# RL6842_IP_SVD register map
Vendor: Realtek
Registers are 32-bit, read-write, reset 0x0 unless marked. A register's access mark holds for its fields unless they carry their own. Offsets are from the block's base; [hi:lo] are bit positions; {n}, {i} and the like mark numbered series; <NAME> marks a mode.

## page6 (part 3 of 3)
Base 0x40000000
0x160C REG_A1_ADDR_MASK reset 0xFFFFFFFF — A1 Addr Mask Register
  [31:0] BIT_A1_ADDR_MASK — mask rx A1 addr [39:8] for test
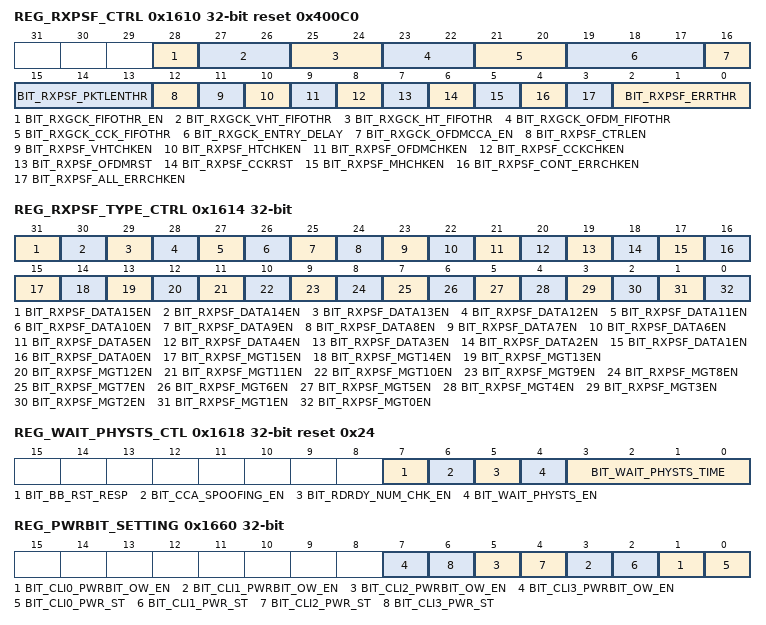
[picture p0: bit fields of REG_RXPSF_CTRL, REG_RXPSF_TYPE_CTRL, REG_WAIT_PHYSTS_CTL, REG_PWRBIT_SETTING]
0x1610 REG_RXPSF_CTRL reset 0x400C0
  [28] BIT_RXGCK_FIFOTHR_EN — 1: enable RXGCK fifo threshold 0: disable RXGCK fifo threshold (ignore fifo threshold) Should be 0 if MAC loopback mode
  [27:26] BIT_RXGCK_VHT_FIFOTHR — VHT rate RXGCK fifo threshold If RXVHT = 1 and RXGCK fifo write pointer >= this threshold, MAC_RX clock will stop gating. 0: 0 1: 1 (minimum RDRDY threshold for avoiding false alarm), can work at all situation. 2: 3 (number of RDRDY before receiving MAC header - 1), may cause error at some situation. 3: 4 (number of RDRDY before receiving MAC header), may cause error at some situation.
  [25:24] BIT_RXGCK_HT_FIFOTHR — HT rate RXGCK fifo threshold If RXHT = 1 and RXGCK fifo write pointer >= this threshold, MAC_RX clock will stop gating. 0: 0 1: 1 (minimum RDRDY threshold for avoiding false alarm), can work at all situation. 2: 2 (number of RDRDY before receiving MAC header - 1), may cause error at some situation. 3: 3 (number of RDRDY before receiving MAC header), may cause error at some situation.
  [23:22] BIT_RXGCK_OFDM_FIFOTHR — OFDM rate RXGCK fifo threshold If OFDM_VBON = 1 and RXGCK fifo write pointer >= this threshold, MAC_RX clock will stop gating. 0: 0 1: 1 (number of RDRDY before receiving MAC header = minimum RDRDY threshold for avoiding false alarm), can work at all situation. 2: 2, may cause error at some situation. 3: 3 (minimum RDRDY number within one packet), may cause error at some situation.
  [21:20] BIT_RXGCK_CCK_FIFOTHR — CCK rate RXGCK fifo threshold If CCKCCA = 1 and RXGCK fifo write pointer >= this threshold, MAC_RX clock will stop gating. 0: 0 1: 1 (minimum RDRDY threshold for avoiding false alarm), can work at all situation. 2: 8, may cause error at some situation. 3: 15 (number of RDRDY before receiving MAC header), may cause error at some situation.
  [19:17] BIT_RXGCK_ENTRY_DELAY — MAC_RX wait some time to gate clock after making the decision (about gating clock). Unit: T (MAC clock cycle) 0: 0 1: 2 2: 4 3: 8 4: 16 5: 32 6: 64 7: 128
  [16] BIT_RXGCK_OFDMCCA_EN — This bit is set to 1 to let OFDMCCA be one of the signals that can wakeup MAC from Rx_idle
  [15:13] BIT_RXPSF_PKTLENTHR — Packet length threshold 3'd0: 16 Bytes 3'd1: 32 Bytes 3'd2: 64 Bytes 3'd3: 128 Bytes 3'd4: 256 Bytes 3'd5: 512 Bytes 3'd6: 1024 Bytes 3'd7: 2048 Bytes Only the packet which packet length is longer than this threshold will trigger an invalid_pkt pulse.
  [12] BIT_RXPSF_CTRLEN — This bit is set to 1 to enable MAC to consider trigging invalid_pkt as rx packet Type=01.
  [11] BIT_RXPSF_VHTCHKEN — This bit is set to 1 to enable MAC to consider trigging invalid_pkt as rx packet rate = VHT
  [10] BIT_RXPSF_HTCHKEN — This bit is set to 1 to enable MAC to consider trigging invalid_pkt as rx packet rate = HT
  [9] BIT_RXPSF_OFDMCHKEN — This bit is set to 1 to enable MAC to consider trigging invalid_pkt as rx packet rate = OFDM
  [8] BIT_RXPSF_CCKCHKEN — This bit is set to 1 to enable MAC to consider trigging invalid_pkt as rx packet rate = CCK
  [7] BIT_RXPSF_OFDMRST — This bit is set to 1 to reset MAC Rx before sending OFDM (include OFDM, HT, VHT) packet triggered invalid_pkt pulse (0 for debug)
  [6] BIT_RXPSF_CCKRST — This bit is set to 1 to reset MAC Rx before sending CCK packet triggered invalid_pkt pulse(0 for debug)
  [5] BIT_RXPSF_MHCHKEN — This bit is set to 1 to enable MAC to inform BB enter power saving mode as rx unmatch my MACID unicast or unmatch my BSSID Broadcast/Mutlicast packets (including aggrigation and non-aggrigation)
  [4] BIT_RXPSF_CONT_ERRCHKEN — This bit is set to 1 to enable MAC to inform BB enter power saving mode as continuous rx FCS error packets number in a PPDU is large than the FCS error packet threshold defined by BBPSF_ERRTHR. This function is independent from rate, type and IDs.
  [3] BIT_RXPSF_ALL_ERRCHKEN — This bit is set to 1 to enable MAC to inform BB enter power saving mode as rx FCS error packets number in a PPDU is larger than the FCS error packet threshold defined by BBPSF_ERRTHR. This function is independent from rate, type and IDs.
  [2:0] BIT_RXPSF_ERRTHR — FCS error packet threshold 3'd0: 1 packet 3'd1: 4 packets 3'd2: 8 packets 3'd3: 12 packets 3'd4: 16 packets 3'd5: 20 packets 3'd6: 24 packets 3'd7: 28 packets
0x1614 REG_RXPSF_TYPE_CTRL
  [31] BIT_RXPSF_DATA15EN — This bit is set to 1 to enable MAC to consider trigging invalid_pkt as rx packet Type=10 and subtype=1111.
  [30] BIT_RXPSF_DATA14EN — This bit is set to 1 to enable MAC to consider trigging invalid_pkt as rx packet Type=10 and subtype=1110.
  [29] BIT_RXPSF_DATA13EN — This bit is set to 1 to enable MAC to consider trigging invalid_pkt as rx packet Type=10 and subtype=1101.
  [28] BIT_RXPSF_DATA12EN — This bit is set to 1 to enable MAC to consider trigging invalid_pkt as rx packet Type=10 and subtype=1100.
  [27] BIT_RXPSF_DATA11EN — This bit is set to 1 to enable MAC to consider trigging invalid_pkt as rx packet Type=10 and subtype=1011.
  [26] BIT_RXPSF_DATA10EN — This bit is set to 1 to enable MAC to consider trigging invalid_pkt as rx packet Type=10 and subtype=1010.
  [25] BIT_RXPSF_DATA9EN — This bit is set to 1 to enable MAC to consider trigging invalid_pkt as rx packet Type=10 and subtype=1001.
  [24] BIT_RXPSF_DATA8EN — This bit is set to 1 to enable MAC to consider trigging invalid_pkt as rx packet Type=10 and subtype=1000.
  [23] BIT_RXPSF_DATA7EN — This bit is set to 1 to enable MAC to consider trigging invalid_pkt as rx packet Type=10 and subtype=0111.
  [22] BIT_RXPSF_DATA6EN — This bit is set to 1 to enable MAC to consider trigging invalid_pkt as rx packet Type=10 and subtype=0110.
  [21] BIT_RXPSF_DATA5EN — This bit is set to 1 to enable MAC to consider trigging invalid_pkt as rx packet Type=10 and subtype=0101.
  [20] BIT_RXPSF_DATA4EN — This bit is set to 1 to enable MAC to consider trigging invalid_pkt as rx packet Type=10 and subtype=0100.
  [19] BIT_RXPSF_DATA3EN — This bit is set to 1 to enable MAC to consider trigging invalid_pkt as rx packet Type=10 and subtype=0011.
  [18] BIT_RXPSF_DATA2EN — This bit is set to 1 to enable MAC to consider trigging invalid_pkt as rx packet Type=10 and subtype=0010.
  [17] BIT_RXPSF_DATA1EN — This bit is set to 1 to enable MAC to consider trigging invalid_pkt as rx packet Type=10 and subtype=0001.
  [16] BIT_RXPSF_DATA0EN — This bit is set to 1 to enable MAC to consider trigging invalid_pkt as rx packet Type=10 and subtype=0000.
  [15] BIT_RXPSF_MGT15EN — This bit is set to 1 to enable MAC to consider trigging invalid_pkt as rx packet Type=00 and subtype=1111.
  [14] BIT_RXPSF_MGT14EN — This bit is set to 1 to enable MAC to consider trigging invalid_pkt as rx packet Type=00 and subtype=1110.
  [13] BIT_RXPSF_MGT13EN — This bit is set to 1 to enable MAC to consider trigging invalid_pkt as rx packet Type=00 and subtype=1101.
  [12] BIT_RXPSF_MGT12EN — This bit is set to 1 to enable MAC to consider trigging invalid_pkt as rx packet Type=00 and subtype=1100.
  [11] BIT_RXPSF_MGT11EN — This bit is set to 1 to enable MAC to consider trigging invalid_pkt as rx packet Type=00 and subtype=1011.
  [10] BIT_RXPSF_MGT10EN — This bit is set to 1 to enable MAC to consider trigging invalid_pkt as rx packet Type=00 and subtype=1010.
  [9] BIT_RXPSF_MGT9EN — This bit is set to 1 to enable MAC to consider trigging invalid_pkt as rx packet Type=00 and subtype=1001.
  [8] BIT_RXPSF_MGT8EN — This bit is set to 1 to enable MAC to consider trigging invalid_pkt as rx packet Type=00 and subtype=1000.
  [7] BIT_RXPSF_MGT7EN — This bit is set to 1 to enable MAC to consider trigging invalid_pkt as rx packet Type=00 and subtype=0111.
  [6] BIT_RXPSF_MGT6EN — This bit is set to 1 to enable MAC to consider trigging invalid_pkt as rx packet Type=00 and subtype=0110.
  [5] BIT_RXPSF_MGT5EN — This bit is set to 1 to enable MAC to consider trigging invalid_pkt as rx packet Type=00 and subtype=0101.
  [4] BIT_RXPSF_MGT4EN — This bit is set to 1 to enable MAC to consider trigging invalid_pkt as rx packet Type=00 and subtype=0100.
  [3] BIT_RXPSF_MGT3EN — This bit is set to 1 to enable MAC to consider trigging invalid_pkt as rx packet Type=00 and subtype=0011.
  [2] BIT_RXPSF_MGT2EN — This bit is set to 1 to enable MAC to consider trigging invalid_pkt as rx packet Type=00 and subtype=0010.
  [1] BIT_RXPSF_MGT1EN — This bit is set to 1 to enable MAC to consider trigging invalid_pkt as rx packet Type=00 and subtype=0001.
  [0] BIT_RXPSF_MGT0EN — This bit is set to 1 to enable MAC to consider trigging invalid_pkt as rx packet Type=00 and subtype=0000.
0x1618 REG_WAIT_PHYSTS_CTL reset 0x24
  [7] BIT_BB_RST_RESP — When set to 1,enable bb/rdrdy_err/cca_spoofing to reset mac and will not tx response
  [6] BIT_CCA_SPOOFING_EN — When set to 1,enable cca_spoofing reset macrx
  [5] BIT_RDRDY_NUM_CHK_EN — When set, enable check rdrdy number is enough or not. If number is not enough will rst macrx
  [4] BIT_WAIT_PHYSTS_EN — When set to 1,enable wait physts rpt valid function
  [3:0] BIT_WAIT_PHYSTS_TIME — Wait physts rpt timeout ,unit us(6us is the recommeded value)
{0x1600+0x10*i} REG_MACID{i} (i=2..4) — MAC ID{i} Register
  [31:0] BIT_MACID{i}_V1 — MAC Identification Number {i} Register
{0x1604+0x10*i} REG_MACID{i}_H (i=2..4) — MAC ID{i} Register
  [15:0] BIT_MACID{i}_H_V1 — MAC Identification Number {i} Register
{0x1608+0x10*i} REG_BSSID{i} (i=2..4) — BSSID{i} Register
  [31:0] BIT_BSSID{i}_V1 — Basic Station Set Identification {i}
{0x160C+0x10*i} REG_BSSID{i}_H (i=2..4) — BSSID{i} Register
  [15:0] BIT_BSSID{i}_H_V1 — Basic Station Set Identification {i}
0x1650 REG_NOA_REPORT
  [31:0] NOA_RPT
0x1654 REG_NOA_REPORT_1
  [31:0] NOA_RPT_1
0x1658 REG_NOA_REPORT_2
  [31:0] NOA_RPT_2
0x165C REG_NOA_REPORT_3
  [7:0] NOA_RPT_3
0x1660 REG_PWRBIT_SETTING
  [2n+1] BIT_CLI{n}_PWRBIT_OW_EN (n=0..3) — For client{n} (port{n+1}). If this bit is set to 1, MAC will overwrite power bit of frame control according to CLI{n}_PWR_ST. (only for data frame)
  [2n] BIT_CLI{n}_PWR_ST (n=0..3) — For client{n} (port{n+1}). MAC will overwrite power bit of frame control according to CLI{n}_PWR_ST.(only for data frame)
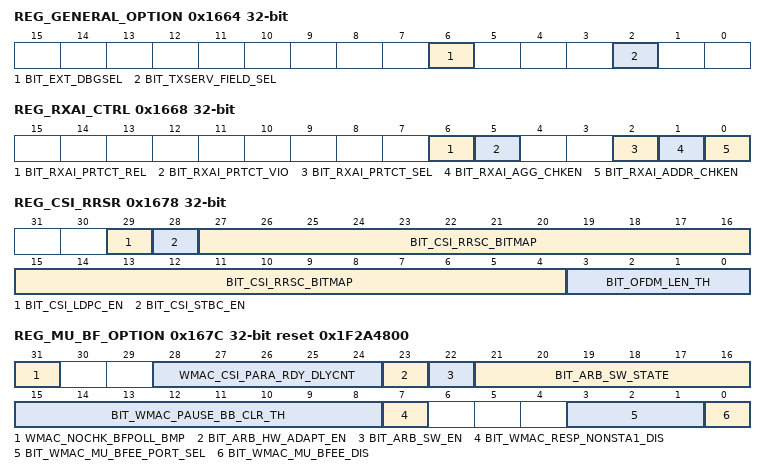
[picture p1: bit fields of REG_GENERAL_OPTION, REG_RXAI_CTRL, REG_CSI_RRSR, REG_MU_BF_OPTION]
0x1664 REG_GENERAL_OPTION
  [6] BIT_EXT_DBGSEL — enable extend dbg port sel
  [2] BIT_TXSERV_FIELD_SEL
0x1668 REG_RXAI_CTRL access per field
  [6] BIT_RXAI_PRTCT_REL ro — If MAC_reset_protect is set to 0 by MAC decision circuit (address/A-MPDU checking), set this bit to 1. Reset by BIT_RXAI_INFO_RST = 1
  [5] BIT_RXAI_PRTCT_VIO ro — If MAC gets BB_reset_MAC pulse when MAC_reset_protect = 1, set this bit to 1. Reset by BIT_RXAI_INFO_RST = 1
  [2] BIT_RXAI_PRTCT_SEL rw — MAC_reset_protect rises at 0: DATA_ON rises 1: PLCP check OK (OFDM/CCK) or receiving 3rd/2nd (VHT/HT) RDRDY
  [1] BIT_RXAI_AGG_CHKEN rw — This bit is only workable when BIT_RXAI_ADDR_CHKEN = 1. 1: if and only if the receiving address matched PPDU is A-MPDU and is not VHT single MPDU, then MAC inform BB not doing reCCA.
  [0] BIT_RXAI_ADDR_CHKEN rw — This bit is set to 1 to enable MAC to inform BB not doing reCCA during receiving the address matched PPDU.
0x166C REG_RX_BCN_TM ro — rx beacon timer
  [15:0] BIT_RX_BCN_TIMER — indicate rx beacon timer from cca up to fcs ok, units us
0x1678 REG_CSI_RRSR
  [29] BIT_CSI_LDPC_EN — Enable LDPC in Tx CSI Frame
  [28] BIT_CSI_STBC_EN — Enable STBC in Tx CSI Frame
  [27:4] BIT_CSI_RRSC_BITMAP — BitMap to indicate the CSI frame rate in this BSS. Each bit is mapped as the following: Bit[4:11] = {6M, 9M, 12M, 18M, 24M, 36M, 48M, 54M} Bit[12:19] = HT MCS0~MCS7 BIT[27:20] = VHT 1SSMCS0~7 The modulation of response rate must be less than or equal to the rate of the initiating frame. If none of the bits are set, no response is generated by Rtl8712. If both legacy rates and HT rates are defined as Basic Rates, fill in only the legacy portion of the bitmap. If only HT rates are defined as Basic Rates, fill in both the legacy and HT portion of the bitmap.
  [3:0] BIT_OFDM_LEN_TH — CSI frame length threshold for using legacy OFDM (unit: 128B). 0 means disabled. If CSI frame length > threshold, search from VHT or HT bitmap If CSI frame length < threshold, search from legacy OFDM bitmap
0x167C REG_MU_BF_OPTION reset 0x1F2A4800
  [31] WMAC_NOCHK_BFPOLL_BMP — Set this bit to ignore retransmission bitmap of rx beamforming report poll
  [28:24] WMAC_CSI_PARA_RDY_DLYCNT — 1:Cycle number from txctl state machine IDLE(VBON falling) to CSI_standby falling. 2:Half of this value is txctl state machine IDLE(VBON falling) to CSI_parameter_ready rising cycle number.
  [23] BIT_ARB_HW_ADAPT_EN — Enable hardware to arbitrate data according to rate offset of user0 and user1
  [22] BIT_ARB_SW_EN — Enable software to set initial state of MU arbiter
  [21:16] BIT_ARB_SW_STATE — MU arbiter software initial state
  [15:8] BIT_WMAC_PAUSE_BB_CLR_TH — MAC_PAUSE_BB High to Low clear threshold of csidma syncff read-write pointer
  [7] BIT_WMAC_RESP_NONSTA1_DIS — Disable response BA when receive non-STA1 user position MU PPDU
  [3:1] BIT_WMAC_MU_BFEE_PORT_SEL — Enable software to set initial state of MU arbiter
  [0] BIT_WMAC_MU_BFEE_DIS — If set to 1, HW will be SU only beamformee and not response to NDPA or Beamforming report poll.
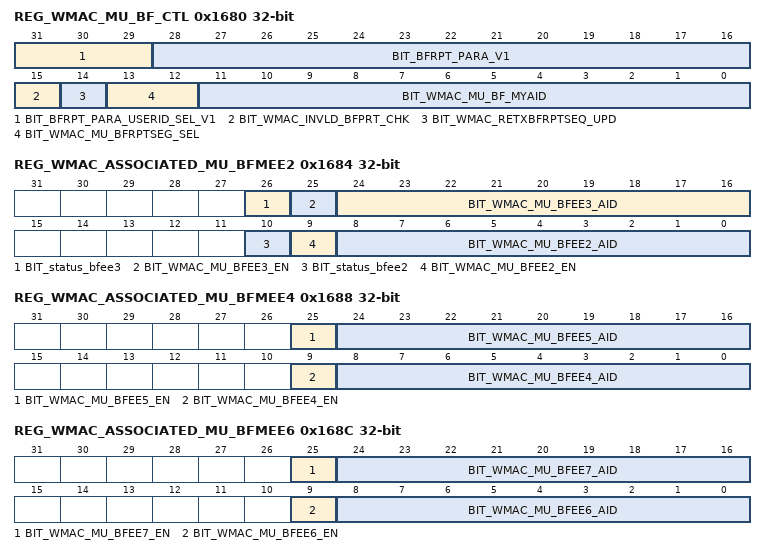
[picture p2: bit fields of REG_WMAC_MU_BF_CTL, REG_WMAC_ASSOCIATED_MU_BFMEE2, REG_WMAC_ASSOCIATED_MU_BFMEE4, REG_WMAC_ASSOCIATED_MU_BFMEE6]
0x1680 REG_WMAC_MU_BF_CTL access per field
  [31:29] BIT_BFRPT_PARA_USERID_SEL_V1 rw — User ID of associated Bfee, MU: 2~7 ,SU:0~1
  [28:16] BIT_BFRPT_PARA_V1 ro — CSI report parameter of selected user ID BFee {bw[1:0],cb[1:0],ng[1:0],nr[2:0],nc[2:0]} ;
  [15] BIT_WMAC_INVLD_BFPRT_CHK rw — Check invalid case of received beamforming report
  [14] BIT_WMAC_RETXBFRPTSEQ_UPD rw — Update sequence number and not set retry bit when retransmit beamforming report.
  [13:12] BIT_WMAC_MU_BFRPTSEG_SEL rw — Beamforming report segment length select 2'h00 :3895 bytes(also means csi segmentation enable),2'h01:7991bytes, 2'h10:11454bytes
  [11:0] BIT_WMAC_MU_BF_MYAID rw — When I'm one of Bfees, my AID12 to identify STA_info in NDPA
0x1684 REG_WMAC_ASSOCIATED_MU_BFMEE2 access per field
  [26] BIT_status_bfee3 ro — beamforming report status of beamformee3 0: fail, 1: success
  [25] BIT_WMAC_MU_BFEE3_EN rw — If enabled, NDPA/BF-rpt-poll would be sent to beamformee3, and CSI rpt of beamformee3 can be read from 0x1682[11:0] when 0x1682[14:12] is 3
  [24:16] BIT_WMAC_MU_BFEE3_AID rw — P_AID of the target beamformee3
  [10] BIT_status_bfee2 ro — beamforming report status of beamformee2 0: fail, 1: success
  [9] BIT_WMAC_MU_BFEE2_EN rw — If enabled, NDPA/BF-rpt-poll would be sent to beamformee2, and CSI rpt of beamformee2 can be read from 0x1682[11:0] when 0x1682[14:12] is 2
  [8:0] BIT_WMAC_MU_BFEE2_AID rw — P_AID of the target beamformee2
0x1688 REG_WMAC_ASSOCIATED_MU_BFMEE4
  [25] BIT_WMAC_MU_BFEE5_EN — If enabled, NDPA/BF-rpt-poll would be sent to beamformee5, and CSI rpt of beamformee5 can be read from 0x1682[11:0] when 0x1682[14:12] is 5
  [24:16] BIT_WMAC_MU_BFEE5_AID — P_AID of the target beamformee5
  [9] BIT_WMAC_MU_BFEE4_EN — If enabled, NDPA/BF-rpt-poll would be sent to beamformee4, and CSI rpt of beamformee4 can be read from 0x1682[11:0] when 0x1682[14:12] is 4
  [8:0] BIT_WMAC_MU_BFEE4_AID — P_AID of the target beamformee4
0x168C REG_WMAC_ASSOCIATED_MU_BFMEE6
  [25] BIT_WMAC_MU_BFEE7_EN — If enabled, NDPA/BF-rpt-poll would be sent to beamformee7, and CSI rpt of beamformee7 can be read from 0x1682[11:0] when 0x1682[14:12] is 7
  [24:16] BIT_WMAC_MU_BFEE7_AID — P_AID of the target beamformee7
  [9] BIT_WMAC_MU_BFEE6_EN — If enabled, NDPA/BF-rpt-poll would be sent to beamformee6, and CSI rpt of beamformee6 can be read from 0x1682[11:0] when 0x1682[14:12] is 6
  [8:0] BIT_WMAC_MU_BFEE6_AID — P_AID of the target beamformee6
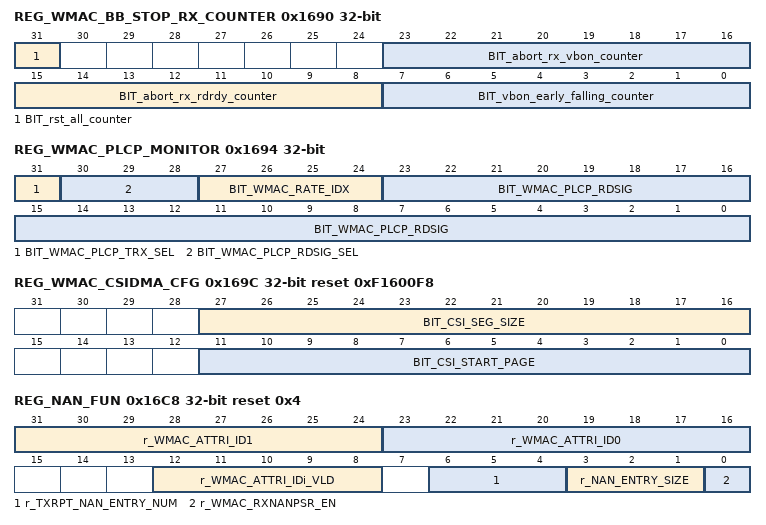
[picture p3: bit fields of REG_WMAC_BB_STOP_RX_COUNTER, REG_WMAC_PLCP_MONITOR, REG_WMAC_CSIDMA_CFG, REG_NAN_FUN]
0x1690 REG_WMAC_BB_STOP_RX_COUNTER ro
  [31] BIT_rst_all_counter — Write one to reset all counters to zero.
  [23:16] BIT_abort_rx_vbon_counter — Increase when mac_abort_rx_vbon trigger. 0x120[29] / 0x124[29] : BB_STOP_RX mask/interrupt 0x0B8[0] / 0x0BC[0] : BB_STOP_RX mask/interrupt Interrupts will be trigger when mac detect any counter of 0x1690 increase.
  [15:8] BIT_abort_rx_rdrdy_counter — Increase when mac_abort_rx_rdrdy trigger 0x120[29] / 0x124[29] : BB_STOP_RX mask/interrupt 0x0B8[0] / 0x0BC[0] : BB_STOP_RX mask/interrupt Interrupts will be trigger when mac detect any counter of 0x1690 increase.
  [7:0] BIT_vbon_early_falling_counter — Increase when VBON fall & no rx plcp error & rx_parser is waiting for rdrdy which is expected but not received . 0x120[29] / 0x124[29] : BB_STOP_RX mask/interrupt 0x0B8[0] / 0x0BC[0] : BB_STOP_RX mask/interrupt Interrupts will be trigger when mac detect any counter of 0x1690 increase.
0x1694 REG_WMAC_PLCP_MONITOR access per field
  [31] BIT_WMAC_PLCP_TRX_SEL rw — Selection of Tx/Rx plcp header 0:Rx 1:Tx
  [30:28] BIT_WMAC_PLCP_RDSIG_SEL rw — Selection of plcp header signal field 0:LSIG/CCK PLCP 1:HTSIG1/VHTSIGA1/HESIGA1 2:HTSIG2/VHTSIGA2/HESIGA2 3:VHTSIGB/HESIGB, low 4bit is dummy 4: HE USER FIELD 5: SERVICE
  [27:24] BIT_WMAC_RATE_IDX ro — PPDU type 0:Long PLCP, 1:Short PLCP, 2: Legacy, 3: HT_MF, 4:HT_GF, 5: VHT-SU, 6: VHT-MU, 7: HE-SU, 8: HE-ER_SU, 9: HE_MU, 10: HE_TB, 11~15:RSVD U(4,0)
  [23:0] BIT_WMAC_PLCP_RDSIG ro — Selected signal field to read out
0x169C REG_WMAC_CSIDMA_CFG reset 0xF1600F8
  [27:16] BIT_CSI_SEG_SIZE — CSI data segmentation size (bytes) = Max. MPDU length - mac hdr (24) - act type (1) - category (1) - mimo ctrl (3) - FCS (4)(default:3862byte)
  [11:0] BIT_CSI_START_PAGE — The starting page number of csi buffer in TXPKTBUF
0x16A0 REG_TRANSMIT_ADDRSS_0 — TA0 Register
  [31:0] BIT_TA0_v1 — Transmitter address for port 0
0x16A4 REG_TRANSMIT_ADDRSS_0_H — TA0 Register
  [15:0] BIT_TA0_H_V1 — Transmitter address for port 0
{0x16A0+8i} REG_TRANSMIT_ADDRSS_{i} (i=1..4) — TA{i} Register
  [31:0] BIT_TA{i}_V1 — Transmitter address for port {i}
0x16AC REG_TRANSMIT_ADDRSS_1_H — TA1 Register
  [15:0] BIT_TA1_H_V1 — Transmitter address for port 1
0x16B4 REG_TRANSMIT_ADDRSS_2_H — TA2 Register)
  [15:0] BIT_TA2_H_V1 — Transmitter address for port 2
0x16BC REG_TRANSMIT_ADDRSS_3_H — TA3 Register
  [15:0] BIT_TA3_H_V1 — Transmitter address for port 3
0x16C4 REG_TRANSMIT_ADDRSS_4_H — TA4 Register
  [15:0] BIT_TA4_H_V1 — Transmitter address for port 4
0x16C8 REG_NAN_FUN reset 0x4
  [31:24] r_WMAC_ATTRI_ID1 — the NAN attribute whose ID is r_WMAC_ATTRI_ID1 will be written into NAN beacon report
  [23:16] r_WMAC_ATTRI_ID0 — the NAN attribute whose ID is r_WMAC_ATTRI_ID0 will be written into NAN beacon report
  [12:8] r_WMAC_ATTRI_IDi_VLD — valid flag bitmap of r_WMAC_ATTRI_IDi
  [6:4] r_TXRPT_NAN_ENTRY_NUM — number of NAN beacon report entry in txrptbuffer
  [3:1] r_NAN_ENTRY_SIZE — size of one NAN beacon report entry, unit is 8byte
  [0] r_WMAC_RXNANPSR_EN — parse enable of rx NAN sync beacon
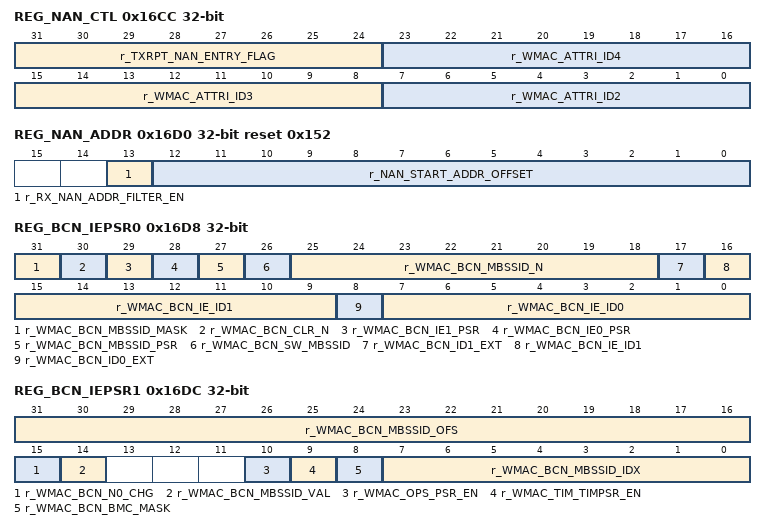
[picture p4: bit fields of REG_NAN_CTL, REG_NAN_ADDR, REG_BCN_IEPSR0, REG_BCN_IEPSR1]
0x16CC REG_NAN_CTL access per field
  [31:24] r_TXRPT_NAN_ENTRY_FLAG ro — indicate NAN beacon report(i) in txrptbuffer is valid, it is set by HW and clear by FW
  [23:16] r_WMAC_ATTRI_ID4 rw — the NAN attribute whose ID is r_WMAC_ATTRI_ID4 will be written into NAN beacon report
  [15:8] r_WMAC_ATTRI_ID3 rw — the NAN attribute whose ID is r_WMAC_ATTRI_ID3 will be written into NAN beacon report
  [7:0] r_WMAC_ATTRI_ID2 rw — the NAN attribute whose ID is r_WMAC_ATTRI_ID2 will be written into NAN beacon report
0x16D0 REG_NAN_ADDR reset 0x152
  [13] r_RX_NAN_ADDR_FILTER_EN — enable of rx nan beacon address filter, can not used in D2 testchip
  [12:0] r_NAN_START_ADDR_OFFSET — Start offset Location of NAN beacon report FIFO. Unit: 8bytes
0x16D4 REG_NAN_ADDR_FLITER
  [31:0] r_RX_NAN_ADDR_FILTER — nan address filter
0x16D8 REG_BCN_IEPSR0
  [31] r_WMAC_BCN_MBSSID_MASK — enable tim no hit don't check whether BC/MC packets are buffered at nontransmitted BSSID
  [30] r_WMAC_BCN_CLR_N — enable clear macbssid indicator when no multiple BSSID element is found.
  [29] r_WMAC_BCN_IE1_PSR — enable parser specified ie 1 element
  [28] r_WMAC_BCN_IE0_PSR — enable parser specified ie0 element
  [27] r_WMAC_BCN_MBSSID_PSR — enable parser multiple BSSID element
  [26] r_WMAC_BCN_SW_MBSSID — enable the MaxBSSID indicator value from SW
  [25:18] r_WMAC_BCN_MBSSID_N — SW write the value of MaxBSSID Indicator field
  [17] r_WMAC_BCN_ID1_EXT — indicate current ie is the extend element which need to parser extend id field
  [16:9] r_WMAC_BCN_IE_ID1 — specified Element ID, set corresponding interrupt when it is parsed
  [8] r_WMAC_BCN_ID0_EXT — indicate current ie is the extend element which need to parser extend id field
  [7:0] r_WMAC_BCN_IE_ID0 — specified Element ID, set corresponding interrupt when it is parsed
0x16DC REG_BCN_IEPSR1 access per field
  [31:16] r_WMAC_BCN_MBSSID_OFS ro — the multiple bssid element offset (byte unit) in frame body
  [15] r_WMAC_BCN_N0_CHG ro — indicate parsed maxmbssid indicator field value has changed which leads to the change of N0.
  [14] r_WMAC_BCN_MBSSID_VAL ro — indicate ofs and n0 change bit is valid.
  [10] r_WMAC_OPS_PSR_EN rw — enable parser ops frame tim elemnt and ops element
  [9] r_WMAC_TIM_TIMPSR_EN rw — enable parser tim frame tim element
  [8] r_WMAC_BCN_BMC_MASK rw — bcn tim hit bc/mc mask
  [7:0] r_WMAC_BCN_MBSSID_IDX rw — the multiple bssid index that current sta connect with
0x16E0 REG_CHINFO_ADDR
  [31:0] r_CHINFO_TX_ADDR_l — low 32bit tx address for trigger channel info
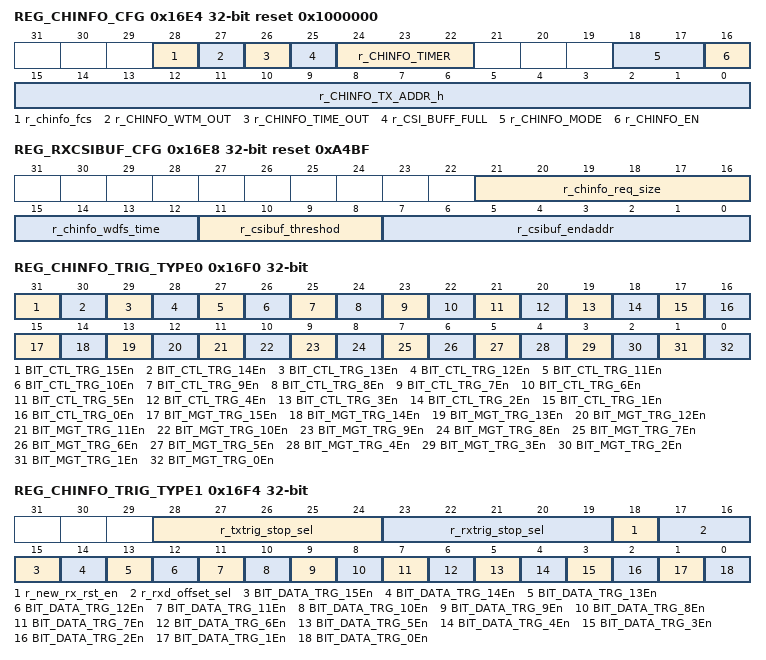
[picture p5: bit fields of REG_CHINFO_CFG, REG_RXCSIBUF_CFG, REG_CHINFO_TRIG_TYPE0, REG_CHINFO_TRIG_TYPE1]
0x16E4 REG_CHINFO_CFG access per field reset 0x1000000
  [28] r_chinfo_fcs rw — when set to 1, will not check channel info fcs ok flag
  [27] r_CHINFO_WTM_OUT ro — BB does't send channel info when timeout occur
  [26] r_CHINFO_TIME_OUT ro — BB send channel info length is less than report length
  [25] r_CSI_BUFF_FULL ro — Indicate rxcsibuff full occur
  [24:22] r_CHINFO_TIMER rw — Wait timeout value after repuest channe info, unit 4 mac clock cycles
  [18:17] r_CHINFO_MODE rw — channel info mode setting. 0: enable normal rx trigger; 1: enable ndpa trigger; note: repsonse mode decided by tx descriptor. Valid when r_CHINFO_EN is 1.
  [16] r_CHINFO_EN rw — enable for getting channel info from BB. When set to 0, will not trigger channel info function
  [15:0] r_CHINFO_TX_ADDR_h rw — high 16bit tx address for trigger channel info
0x16E8 REG_RXCSIBUF_CFG reset 0xA4BF
  [21:16] r_chinfo_req_size — The channel info trigger request rxcsibuffer size, unit 32bytes, the actually request size = (r_chinfo_req_size + 1) * 32byte
  [15:12] r_chinfo_wdfs_time — Wait DFS timeout value, unit 4 mac clock cycles
  [11:8] r_csibuf_threshod — rxcsibuffer full threshold, size must greater than or equal to csi descriptors
  [7:0] r_csibuf_endaddr — End address of rxcsibuffer, unit 8bytes. Rxcsibuffer is 1536 bytes
0x16EC REG_BT_ZB_COEX_TB
  [31:0] r_bt_zb_coex_table — bt and zigbee coexist table
0x16F0 REG_CHINFO_TRIG_TYPE0
  [31] BIT_CTL_TRG_15En — When set, control frames with type=01 and subtype=1111 will trigger channel info
  [30] BIT_CTL_TRG_14En — When set, control frames with type=01 and subtype=1110 will trigger channel info
  [29] BIT_CTL_TRG_13En — When set, control frames with type=01 and subtype=1101 will trigger channel info
  [28] BIT_CTL_TRG_12En — When set, control frames with type=01 and subtype=1100 will trigger channel info
  [27] BIT_CTL_TRG_11En — When set, control frames with type=01 and subtype=1011 will trigger channel info
  [26] BIT_CTL_TRG_10En — When set, control frames with type=01 and subtype=1010 will trigger channel info
  [25] BIT_CTL_TRG_9En — When set, control frames with type=01 and subtype=1001 will trigger channel info
  [24] BIT_CTL_TRG_8En — When set, control frames with type=01 and subtype=1000 will trigger channel info
  [23] BIT_CTL_TRG_7En — When set, control frames with type=01 and subtype=0111 will trigger channel info
  [22] BIT_CTL_TRG_6En — When set, control frames with type=01 and subtype=0110 will trigger channel info
  [21] BIT_CTL_TRG_5En — When set, control frames with type=01 and subtype=0101 will trigger channel info
  [20] BIT_CTL_TRG_4En — When set, control frames with type=01 and subtype=0100 will trigger channel info
  [19] BIT_CTL_TRG_3En — When set, control frames with type=01 and subtype=0011 will trigger channel info
  [18] BIT_CTL_TRG_2En — When set, control frames with type=01 and subtype=0010 will trigger channel info
  [17] BIT_CTL_TRG_1En — When set, control frames with type=01 and subtype=0001 will trigger channel info
  [16] BIT_CTL_TRG_0En — When set, control frames with type=01 and subtype=0000 will trigger channel info
  [15] BIT_MGT_TRG_15En — When set, management frames with type=00 and subtype=1111 will trigger channel info
  [14] BIT_MGT_TRG_14En — When set, management frames with type=00 and subtype=1110 will trigger channel info
  [13] BIT_MGT_TRG_13En — When set, management frames with type=00 and subtype=1101 will trigger channel info
  [12] BIT_MGT_TRG_12En — When set, management frames with type=00 and subtype=1100 will trigger channel info
  [11] BIT_MGT_TRG_11En — When set, management frames with type=00 and subtype=1011 will trigger channel info
  [10] BIT_MGT_TRG_10En — When set, management frames with type=00 and subtype=1010 will trigger channel info
  [9] BIT_MGT_TRG_9En — When set, management frames with type=00 and subtype=1001 will trigger channel info
  [8] BIT_MGT_TRG_8En — When set, management frames with type=00 and subtype=1000 will trigger channel info
  [7] BIT_MGT_TRG_7En — When set, management frames with type=00 and subtype=0111 will trigger channel info
  [6] BIT_MGT_TRG_6En — When set, management frames with type=00 and subtype=0110 will trigger channel info
  [5] BIT_MGT_TRG_5En — When set, management frames with type=00 and subtype=0101 will trigger channel info
  [4] BIT_MGT_TRG_4En — When set, management frames with type=00 and subtype=0100 will trigger channel info
  [3] BIT_MGT_TRG_3En — When set, management frames with type=00 and subtype=0011 will trigger channel info
  [2] BIT_MGT_TRG_2En — When set, management frames with type=00 and subtype=0010 will trigger channel info
  [1] BIT_MGT_TRG_1En — When set, management frames with type=00 and subtype=0001 will trigger channel info
  [0] BIT_MGT_TRG_0En — When set, management frames with type=00 and subtype=0000 will trigger channel info
0x16F4 REG_CHINFO_TRIG_TYPE1
  [28:24] r_txtrig_stop_sel — select tx trigger stop signal for LA dump
  [23:19] r_rxtrig_stop_sel — select rx trigger stop signal for LA dump
  [18] r_new_rx_rst_en — when set, enable new rx rst macrx when macrx is active
  [17:16] r_rxd_offset_sel — select 2bytes of rxd to debug port 0: 0~1 bytes; 1: 2~3 bytes; 2: 4~5 bytes; 3: 6~7 bytes;
  [15] BIT_DATA_TRG_15En — When set, data frames with type=10 and subtype=1111 will trigger channel info
  [14] BIT_DATA_TRG_14En — When set, data frames with type=10 and subtype=1110 will trigger channel info
  [13] BIT_DATA_TRG_13En — When set, data frames with type=10 and subtype=1101 will trigger channel info
  [12] BIT_DATA_TRG_12En — When set, data frames with type=10 and subtype=1100 will trigger channel info
  [11] BIT_DATA_TRG_11En — When set, data frames with type=10 and subtype=1011 will trigger channel info
  [10] BIT_DATA_TRG_10En — When set, data frames with type=10 and subtype=1010 will trigger channel info
  [9] BIT_DATA_TRG_9En — When set, data frames with type=10 and subtype=1001 will trigger channel info
  [8] BIT_DATA_TRG_8En — When set, data frames with type=10 and subtype=1000 will trigger channel info
  [7] BIT_DATA_TRG_7En — When set, data frames with type=10 and subtype=0111 will trigger channel info
  [6] BIT_DATA_TRG_6En — When set, data frames with type=10 and subtype=0110 will trigger channel info
  [5] BIT_DATA_TRG_5En — When set, data frames with type=10 and subtype=0101 will trigger channel info
  [4] BIT_DATA_TRG_4En — When set, data frames with type=10 and subtype=0100 will trigger channel info
  [3] BIT_DATA_TRG_3En — When set, data frames with type=10 and subtype=0011 will trigger channel info
  [2] BIT_DATA_TRG_2En — When set, data frames with type=10 and subtype=0010 will trigger channel info
  [1] BIT_DATA_TRG_1En — When set, data frames with type=10 and subtype=0001 will trigger channel info
  [0] BIT_DATA_TRG_0En — When set, data frames with type=10 and subtype=0000 will trigger channel info
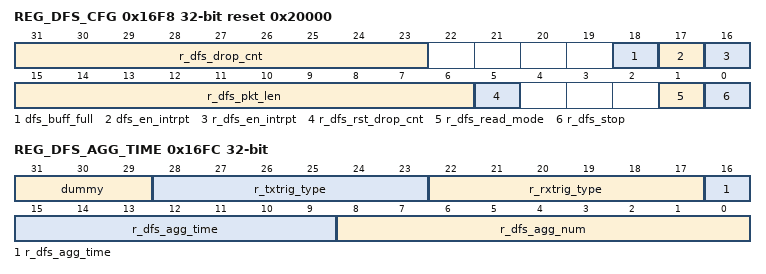
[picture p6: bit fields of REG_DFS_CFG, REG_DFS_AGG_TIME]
0x16F8 REG_DFS_CFG access per field reset 0x20000
  [31:23] r_dfs_drop_cnt ro — drop dfs packets number when dfsbuffer is full
  [18] dfs_buff_full ro — dfs buffer is full
  [17] dfs_en_intrpt ro — When valid, enable generate dfs interrupt
  [16] r_dfs_en_intrpt wo — When set to 1, enable generate DFS interrupt, one pulse
  [15:6] r_dfs_pkt_len ro — dfs packet length need Host to read, 4 bytes unit
  [5] r_dfs_rst_drop_cnt wo — When set to 1, clear r_dfs_drop_cnt, one pulse
  [1] r_dfs_read_mode rw — When set to 1,means host read mode for debug
  [0] r_dfs_stop rw — When set to 1, stop to get DFS from BB and clear the DFS buffer
0x16FC REG_DFS_AGG_TIME
  [31:29] dummy
  [28:23] r_txtrig_type — mapping to frame control type and subtype filed, for LA trigger select
  [22:17] r_rxtrig_type — mapping to frame control type and subtype filed, for LA trigger select
  [16:9] r_dfs_agg_time — DFS packet aggregation time. When reach the target, will inform host by interrupt, unit ms
  [8:0] r_dfs_agg_num — aggregation DFS packet number selection. When reach the target, will inform host by interrupt, unit 4bytes
